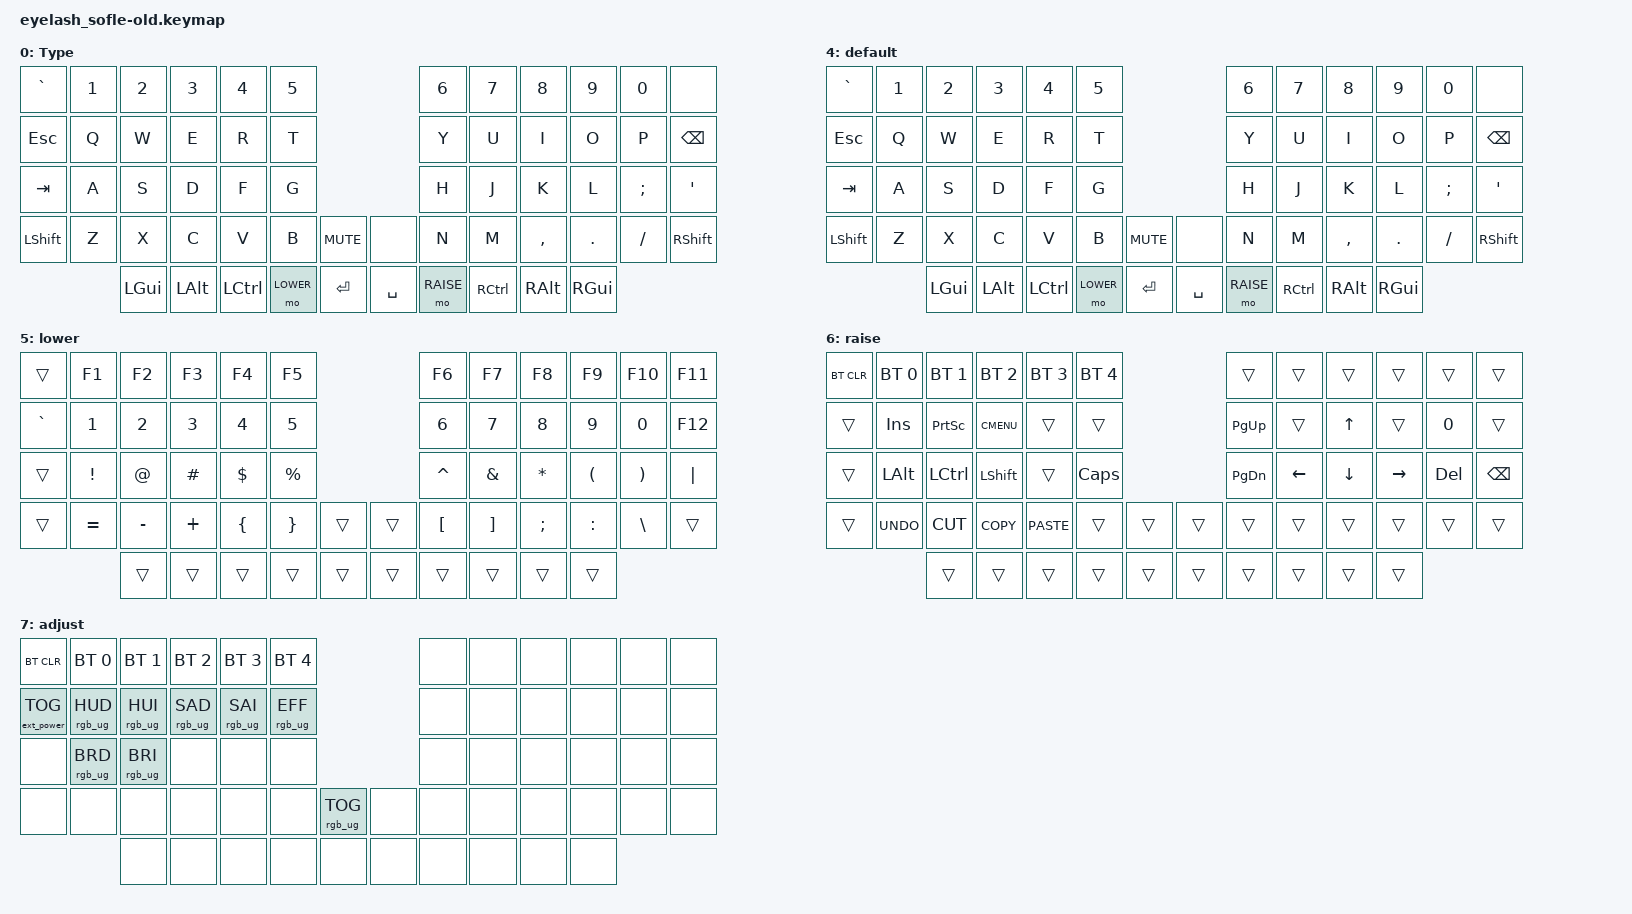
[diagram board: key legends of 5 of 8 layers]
#define ZMK_POINTING_DEFAULT_MOVE_VAL 1200  // 600
#define ZMK_POINTING_DEFAULT_SCRL_VAL 25   // 10

#include <input/processors.dtsi>
#include <zephyr/dt-bindings/input/input-event-codes.h>
#include <behaviors.dtsi>
#include <dt-bindings/zmk/bt.h>
#include <dt-bindings/zmk/ext_power.h>
#include <dt-bindings/zmk/keys.h>
#include <dt-bindings/zmk/pointing.h>
#include <dt-bindings/zmk/rgb.h>
#include <dt-bindings/zmk/outputs.h>

&mmv_input_listener { input-processors = <&zip_xy_scaler 2 1>; };

&msc_input_listener { input-processors = <&zip_scroll_scaler 2 1>; };

&msc {
    acceleration-exponent = <1>;      // 0
    time-to-max-speed-ms = <100>;       // 300
    delay-ms = <0>;                   // 0
};

&mmv {
    time-to-max-speed-ms = <500>;
    acceleration-exponent = <1>;
    trigger-period-ms = <16>;
};

/ {

    scroll_encoder: scroll_encoder {
        compatible = "zmk,behavior-sensor-rotate";
        #sensor-binding-cells = <0>;
        bindings = <&msc SCRL_DOWN>, <&msc SCRL_UP>;
        tap-ms = <100>;
    };

    keymap {
        compatible = "zmk,keymap";

        layer0 {
            display-name = "default";
// ------------------------------------------------------------------------------------------------------------
// |   `   |  1  |  2  |  3   |  4   |  5   |                   |  6   |  7    |  8    |  9   |   0   |       |
// |  ESC  |  Q  |  W  |  E   |  R   |  T   |                   |  Y   |  U    |  I    |  O   |   P   | BKSPC |
// |  TAB  |  A  |  S  |  D   |  F   |  G   |                   |  H   |  J    |  K    |  L   |   ;   |   '   |
// | SHIFT |  Z  |  X  |  C   |  V   |  B   |  MUTE  |  |       |  N   |  M    |  ,    |  .   |   /   | SHIFT |
//               | GUI | ALT  | CTRL | LOWER|  ENTER |  | SPACE | RAISE| CTRL  | ALT   | GUI  |
            bindings = <
&kp GRAVE &kp N1 &kp N2   &kp N3   &kp N4    &kp N5                           &kp N6 &kp N7    &kp N8    &kp N9   &kp N0   &none
&kp ESC   &kp Q  &kp W    &kp E    &kp R     &kp T                            &kp Y  &kp U     &kp I     &kp O    &kp P    &kp BSPC
&kp TAB   &kp A  &kp S    &kp D    &kp F     &kp G                            &kp H  &kp J     &kp K     &kp L    &kp SEMI &kp SQT
&kp LSHFT &kp Z  &kp X    &kp C    &kp V     &kp B      &kp C_MUTE &none      &kp N  &kp M     &kp COMMA &kp DOT  &kp FSLH &kp RSHFT
                 &kp LGUI &kp LALT &kp LCTRL &mo LOWER  &kp RET    &kp SPACE  &mo RAISE  &kp RCTRL &kp RALT  &kp RGUI
            >;

            sensor-bindings = <&inc_dec_kp C_VOLUME_UP C_VOL_DN>;
            display-name = "Type";
        };

        layer_1 {
            bindings = <
&kp GRAVE   &kp F1           &kp F2          &kp F3           &kp F4           &kp F5             &mmv MOVE_UP     &kp F6           &kp F7           &kp F8      &kp F9     &kp F10           &trans
&trans      &kp GRAVE        &mkp LCLK       &mkp MCLK        &mkp RCLK        &mkp MB4           &mmv MOVE_DOWN   &kp PG_UP        &kp END          &kp UP      &kp HOME   &kp MINUS         &kp EQUAL
&trans      &kp TILDE        &trans          &trans           &trans           &mkp MB5           &mmv MOVE_LEFT   &kp PG_DN        &kp LEFT         &kp DOWN    &kp RIGHT  &kp LEFT_BRACKET  &kp RIGHT_BRACKET
&trans      &rgb_ug RGB_OFF  &rgb_ug RGB_ON  &rgb_ug RGB_EFF  &rgb_ug RGB_EFR  &rgb_ug RGB_SPI    &mmv MOVE_RIGHT  &rgb_ug RGB_BRI  &rgb_ug RGB_BRD  &kp INSERT  &kp F11    &kp F12           &trans
&kp C_MUTE  &trans           &trans          &trans           &trans           &trans             &mkp LCLK        &trans           &trans           &trans      &trans     &trans
            >;

            display-name = "Navigate";
            sensor-bindings = <&scroll_encoder>;
        };

        layer_2 {
            bindings = <
&kp TILDE  &bt BT_SEL 0  &bt BT_SEL 1    &bt BT_SEL 2  &bt BT_SEL 3  &bt BT_SEL 4    &mmv MOVE_UP     &kp F6  &kp F7  &kp F8      &kp F9     &kp F10      &trans
&trans     &bt BT_CLR    &bt BT_CLR_ALL  &trans        &trans        &trans          &mmv MOVE_DOWN   &trans  &trans  &kp F11     &kp F12    &kp UNDER    &kp PLUS
&trans     &out OUT_USB  &out OUT_BLE    &trans        &trans        &trans          &mmv MOVE_LEFT   &trans  &trans  &trans      &trans     &kp LBRC     &kp RBRC
&trans     &sys_reset    &trans          &bootloader   &trans        &trans          &mmv MOVE_RIGHT  &trans  &trans  &sys_reset  &soft_off  &bootloader  &trans
&trans     &trans        &trans          &trans        &trans        &trans          &mkp LCLK        &trans  &trans  &trans      &trans     &trans
            >;

            sensor-bindings = <&scroll_encoder>;
        };

        layer_3 {
            bindings = <
&trans  &trans  &trans  &trans  &trans  &trans    &trans  &trans  &trans  &trans  &trans  &trans  &trans
&trans  &trans  &trans  &trans  &trans  &trans    &trans  &trans  &trans  &trans  &trans  &trans  &trans
&trans  &trans  &trans  &trans  &trans  &trans    &trans  &trans  &trans  &trans  &trans  &trans  &trans
&trans  &trans  &trans  &trans  &trans  &trans    &trans  &trans  &trans  &trans  &trans  &trans  &trans
&trans  &trans  &trans  &trans  &trans  &trans    &trans  &trans  &trans  &trans  &trans  &trans
            >;
        };
    };
};


#define BASE 0
#define LOWER 1
#define RAISE 2
#define ADJUST 3

/ {

   // Activate ADJUST layer by pressing raise and lower
    conditional_layers {
        compatible = "zmk,conditional-layers";
        adjust_layer {
            if-layers = <LOWER RAISE>;
            then-layer = <ADJUST>;
        };
    };

    scroll_encoder: scroll_encoder {
        compatible = "zmk,behavior-sensor-rotate";
        #sensor-binding-cells = <0>;
        bindings = <&msc SCRL_DOWN>, <&msc SCRL_UP>;
        tap-ms = <100>;
    };

    keymap {
        compatible = "zmk,keymap";
        default_layer {
// ------------------------------------------------------------------------------------------------------------
// |   `   |  1  |  2  |  3   |  4   |  5   |                   |  6   |  7    |  8    |  9   |   0   |       |
// |  ESC  |  Q  |  W  |  E   |  R   |  T   |                   |  Y   |  U    |  I    |  O   |   P   | BKSPC |
// |  TAB  |  A  |  S  |  D   |  F   |  G   |                   |  H   |  J    |  K    |  L   |   ;   |   '   |
// | SHIFT |  Z  |  X  |  C   |  V   |  B   |  MUTE  |  |       |  N   |  M    |  ,    |  .   |   /   | SHIFT |
//               | GUI | ALT  | CTRL | LOWER|  ENTER |  | SPACE | RAISE| CTRL  | ALT   | GUI  |
            display-name = "default";
            sensor-bindings = <&scroll_encoder &inc_dec_kp C_VOL_UP C_VOL_DN &inc_dec_kp PG_UP PG_DN>;
            bindings = <
&kp GRAVE &kp N1 &kp N2   &kp N3   &kp N4    &kp N5                           &kp N6 &kp N7    &kp N8    &kp N9   &kp N0   &none
&kp ESC   &kp Q  &kp W    &kp E    &kp R     &kp T                            &kp Y  &kp U     &kp I     &kp O    &kp P    &kp BSPC
&kp TAB   &kp A  &kp S    &kp D    &kp F     &kp G                            &kp H  &kp J     &kp K     &kp L    &kp SEMI &kp SQT
&kp LSHFT &kp Z  &kp X    &kp C    &kp V     &kp B      &kp C_MUTE &none      &kp N  &kp M     &kp COMMA &kp DOT  &kp FSLH &kp RSHFT
                 &kp LGUI &kp LALT &kp LCTRL &mo LOWER  &kp RET    &kp SPACE  &mo RAISE  &kp RCTRL &kp RALT  &kp RGUI
            >;
        };

        lower_layer {
            display-name = "lower";
            sensor-bindings = <&scroll_encoder &inc_dec_kp C_VOL_UP C_VOL_DN &inc_dec_kp PG_UP PG_DN>;
// TODO: Some binds are waiting for shifted keycode support.
// ------------------------------------------------------------------------------------------------------------
// |       |  F1 |  F2 |  F3  |  F4  |  F5  |                   |  F6  |  F7   |  F8   |  F9  |  F10  |  F11  |
// |   `   |  1  |  2  |  3   |  4   |  5   |                   |  6   |  7    |  8    |  9   |   0   |  F12  |
// |       |  !  |  @  |  #   |  $   |  %   |                   |  ^   |  &    |  *    |  (   |   )   |   |   |
// |       |  =  |  -  |  +   |  {   |  }   |        |  |       |  [   |  ]    |  ;    |  :   |   \   |       |
//               |     |      |      |      |        |  |       |      |       |       |      |
            bindings = <
&trans    &kp F1    &kp F2    &kp F3      &kp F4    &kp F5                    &kp F6    &kp F7   &kp F8    &kp F9    &kp F10   &kp F11
&kp GRAVE &kp N1    &kp N2    &kp N3      &kp N4    &kp N5                    &kp N6    &kp N7   &kp N8    &kp N9    &kp N0    &kp F12
&trans    &kp EXCL  &kp AT    &kp HASH    &kp DLLR  &kp PRCNT                 &kp CARET &kp AMPS &kp ASTRK &kp LPAR  &kp RPAR  &kp PIPE
&trans    &kp EQUAL &kp MINUS &kp PLUS &kp LBRC  &kp RBRC   &trans &trans  &kp LBKT  &kp RBKT &kp SEMI  &kp COLON &kp BSLH  &trans
                    &trans    &trans      &trans    &trans     &trans &trans  &trans    &trans   &trans    &trans
            >;
        };

        raise_layer {
// ------------------------------------------------------------------------------------------------------------
// | BTCLR | BT1  | BT2  |  BT3  |  BT4  |  BT5 |                |      |      |       |      |       |       |
// |       | INS  | PSCR | GUI   |       |      |                | PGUP |      |   ^   |      |       |       |
// |       | ALT  | CTRL | SHIFT |       | CAPS |                | PGDN |   <- |   v   |  ->  |  DEL  | BKSPC |
// |       | UNDO | CUT  | COPY  | PASTE |      |      |  |      |      |      |       |      |       |       |
//                |      |       |       |      |      |  |      |      |      |       |      |
            display-name = "raise";
            sensor-bindings = <&scroll_encoder &inc_dec_kp C_VOL_UP C_VOL_DN &inc_dec_kp PG_UP PG_DN>;
            bindings = <
&bt BT_CLR &bt BT_SEL 0 &bt BT_SEL 1 &bt BT_SEL 2 &bt BT_SEL 3 &bt BT_SEL 4                  &trans    &trans    &trans   &trans    &trans  &trans
&trans     &kp INS      &kp PSCRN    &kp K_CMENU  &trans       &trans                        &kp PG_UP &trans    &kp UP   &trans    &kp N0  &trans
&trans     &kp LALT     &kp LCTRL    &kp LSHFT    &trans       &kp CLCK                      &kp PG_DN &kp LEFT  &kp DOWN &kp RIGHT &kp DEL &kp BSPC
&trans     &kp K_UNDO   &kp K_CUT    &kp K_COPY   &kp K_PASTE  &trans        &trans  &trans  &trans    &trans    &trans   &trans    &trans  &trans
                        &trans       &trans       &trans       &trans        &trans  &trans  &trans    &trans    &trans   &trans
            >;
        };

        adjust_layer {
// ----------------------------------------------------------------------------------------------------------------------------
// | BTCLR  |  BT1    |  BT2    |   BT3   |   BT4   |   BT5   |                  |      |      |       |      |       |       |
// | EXTPWR | RGB_HUD | RGB_HUI | RGB_SAD | RGB_SAI | RGB_EFF |                  |      |      |       |      |       |       |
// |        | RGB_BRD | RGB_BRI |         |         |         |                  |      |      |       |      |       |       |
// |        |         |         |         |         |         | RGB_TOG | |      |      |      |       |      |       |       |
//                    |         |         |         |         |         | |      |      |      |       |      |
            display-name = "adjust";
            sensor-bindings = <&scroll_encoder &inc_dec_kp C_VOL_UP C_VOL_DN &inc_dec_kp PG_UP PG_DN>;
            bindings = <
&bt BT_CLR        &bt BT_SEL 0    &bt BT_SEL 1    &bt BT_SEL 2    &bt BT_SEL 3    &bt BT_SEL 4                            &none &none &none &none &none &none
&ext_power EP_TOG &rgb_ug RGB_HUD &rgb_ug RGB_HUI &rgb_ug RGB_SAD &rgb_ug RGB_SAI &rgb_ug RGB_EFF                         &none &none &none &none &none &none
&none             &rgb_ug RGB_BRD &rgb_ug RGB_BRI &none           &none           &none                                   &none &none &none &none &none &none
&none             &none           &none           &none           &none           &none            &rgb_ug RGB_TOG &none  &none &none &none &none &none &none
                                  &none           &none           &none           &none            &none           &none  &none &none &none &none
            >;
        };

    };
};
